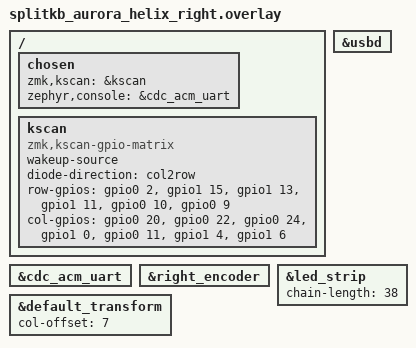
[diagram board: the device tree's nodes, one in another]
/*
 * Copyright (c) 2023 The ZMK Contributors
 *
 * SPDX-License-Identifier: MIT
 */

#include "splitkb_aurora_helix.dtsi"

/ {
    chosen {
        zmk,kscan = &kscan;
        zephyr,console = &cdc_acm_uart;
    };

    kscan: kscan {
        compatible = "zmk,kscan-gpio-matrix";
        wakeup-source;

        diode-direction = "col2row";

        row-gpios
          = <&gpio0 2  (GPIO_ACTIVE_HIGH | GPIO_PULL_DOWN)>,  /* Row 0 */
            <&gpio1 15 (GPIO_ACTIVE_HIGH | GPIO_PULL_DOWN)>,  /* Row 1 */
            <&gpio1 13 (GPIO_ACTIVE_HIGH | GPIO_PULL_DOWN)>,  /* Row 2 */
            <&gpio1 11 (GPIO_ACTIVE_HIGH | GPIO_PULL_DOWN)>,  /* Row 3 */
            <&gpio0 10 (GPIO_ACTIVE_HIGH | GPIO_PULL_DOWN)>,  /* Row 4 */
            <&gpio0 9  (GPIO_ACTIVE_HIGH | GPIO_PULL_DOWN)>;  /* Row 5 */

            ;

        col-gpios
         = <&gpio0 20 (GPIO_ACTIVE_HIGH | GPIO_PULL_DOWN)>,  /* Col 0 */
            <&gpio0 22 (GPIO_ACTIVE_HIGH | GPIO_PULL_DOWN)>,  /* Col 1 */
            <&gpio0 24 (GPIO_ACTIVE_HIGH | GPIO_PULL_DOWN)>,  /* Col 2 */
            <&gpio1 0  (GPIO_ACTIVE_HIGH | GPIO_PULL_DOWN)>,  /* Col 3 */
            <&gpio0 11 (GPIO_ACTIVE_HIGH | GPIO_PULL_DOWN)>,  /* Col 4 */
            <&gpio1 4  (GPIO_ACTIVE_HIGH | GPIO_PULL_DOWN)>,  /* Col 5 */
            <&gpio1 6  (GPIO_ACTIVE_HIGH | GPIO_PULL_DOWN)>;  /* Col 6 */
            ;
    };
};

&usbd {
    status = "okay";
};

&cdc_acm_uart {
    status = "okay";
};


&right_encoder {
    status = "okay";
};

&default_transform {
    col-offset = <7>;
};

&led_strip {
       // chain-length = <6>;
       chain-length = <38>; // Uncomment if using both per-key and underglow LEDs
       // chain-length = <32>; // Uncomment if using only per-key LEDs.
};
